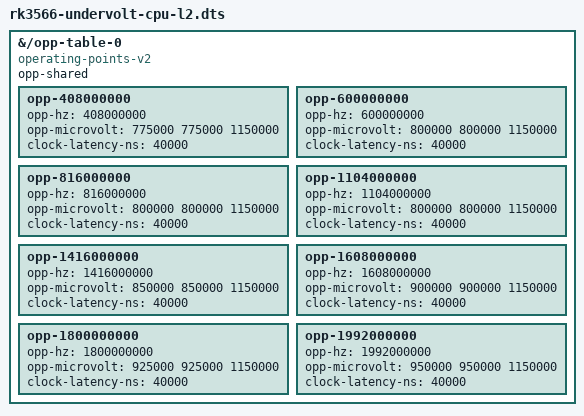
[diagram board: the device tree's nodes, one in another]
/dts-v1/;
/plugin/;

/ {
    fragment@0 {
        target-path = "/opp-table-0";

        __overlay__ {
		    compatible = "operating-points-v2";
		    opp-shared;

            opp-408000000 {
                opp-hz = /bits/ 64 <408000000>;
                opp-microvolt = <775000 775000 1150000>;
                clock-latency-ns = <40000>;
            };

            opp-600000000 {
                opp-hz = /bits/ 64 <600000000>;
                opp-microvolt = <800000 800000 1150000>;
                clock-latency-ns = <40000>;
            };

            opp-816000000 {
                opp-hz = /bits/ 64 <816000000>;
                opp-microvolt = <800000 800000 1150000>;
                clock-latency-ns = <40000>;
            };

            opp-1104000000 {
                opp-hz = /bits/ 64 <1104000000>;
                opp-microvolt = <800000 800000 1150000>;
                clock-latency-ns = <40000>;
            };

            opp-1416000000 {
                opp-hz = /bits/ 64 <1416000000>;
                opp-microvolt = <850000 850000 1150000>;
                clock-latency-ns = <40000>;
            };

            opp-1608000000 {
                opp-hz = /bits/ 64 <1608000000>;
                opp-microvolt = <900000 900000 1150000>;
                clock-latency-ns = <40000>;
            };

            opp-1800000000 {
                opp-hz = /bits/ 64 <1800000000>;
                opp-microvolt = <925000 925000 1150000>;
                clock-latency-ns = <40000>;
            };

            opp-1992000000 {
                opp-hz = /bits/ 64 <1992000000>;
                opp-microvolt = <950000 950000 1150000>;
                clock-latency-ns = <40000>;
            };
        };
    };
};
